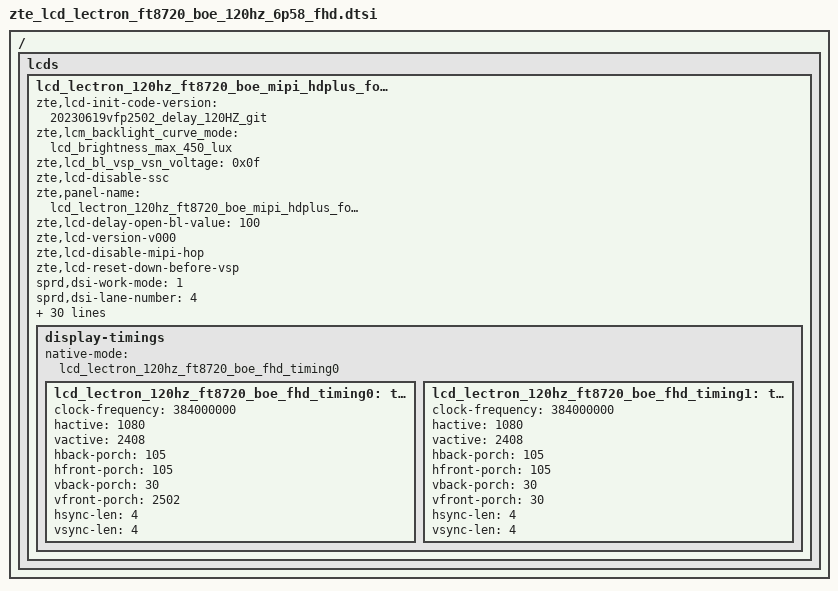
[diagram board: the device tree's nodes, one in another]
/ {
	fragment {
		target-path = "/";
		__overlay__ {
			lcds {
				lcd_lectron_120hz_ft8720_boe_mipi_hdplus_focal: lcd_lectron_120hz_ft8720_boe_mipi_hdplus_focal {
					zte,lcd-init-code-version = "20230619vfp2502_delay_120HZ_git";

					zte,lcm_backlight_curve_mode = "lcd_brightness_max_450_lux";
					zte,lcd_bl_vsp_vsn_voltage = <0x0f>;
					zte,lcd-disable-ssc;
					zte,panel-name = "lcd_lectron_120hz_ft8720_boe_mipi_hdplus_focal_vrr-3";
					zte,lcd-delay-open-bl-value = <100>;
					zte,lcd-version-v000;
					zte,lcd-disable-mipi-hop;
					zte,lcd-reset-down-before-vsp;

					sprd,dsi-work-mode = <1>;
					sprd,dsi-lane-number = <4>;
					sprd,dsi-color-format = "dsc";
					sprd,phy-bit-clock = <1100000>;
					sprd,phy-escape-clock = <20000>;/* kHz */

					sprd,width-mm = <68430>;
					sprd,height-mm = <152570>;
					sprd,vrr-enabled;
					sprd,vrr-max-layers = <3>;
					sprd,slice-width = <540>;
					sprd,slice-height = <8>;
					sprd,output-bpc = <8>;
					sprd,dsc-enable = <1>;
					sprd,dual-dsi-enable = <0>;
					zte,dsc-mode = <5>;

					sprd,esd-check-enable = <1>;/* 0:close , 1:open */
					sprd,esd-check-mode = <1>;/* 0:REG ,1:TE  */
					sprd,esd-check-period = <2000>;
					sprd,esd-check-register = <0x0A>;
					sprd,esd-check-value = <0x9C>;

					sprd,dphy-taget-val = <5>;

					sprd,reset-on-sequence = <1 5>, <0 10>, <1 35>;
					sprd,reset-off-sequence = <1 20>;

					sprd,use-gen-write;
					sprd,initial-command = [
29 00 00 02 00 00
29 00 00 04 FF 87 20 01
29 00 00 02 00 80
29 00 00 03 FF 87 20
29 00 00 02 00 00
29 00 00 05 2A 00 00 04 37
29 00 00 02 00 00
29 00 00 05 2B 00 00 09 67
29 00 00 02 00 A3
29 00 00 05 B3 09 68 00 18
29 00 00 02 00 80
29 00 00 07 C0 00 4B 00 2E 00 12
29 00 00 02 00 90
29 00 00 07 C0 00 4B 00 2E 00 12
29 00 00 02 00 A0
29 00 00 07 C0 00 62 03 F8 00 12
29 00 00 02 00 B0
29 00 00 06 C0 00 C1 00 2E 12
29 00 00 02 00 60
29 00 00 07 C0 00 A6 00 2E 00 12
29 00 00 02 00 70
29 00 00 0D C0 00 C4 00 C8 0F 02 CF 00 00 13 01 56
29 00 00 02 00 A3
29 00 00 07 C1 00 6E 00 34 00 02
29 00 00 02 00 80
29 00 00 11 CE 01 81 FF FF 00 FC 01 00 00 00 00 00 00 84 00 84
29 00 00 02 00 90
29 00 00 10 CE 00 AD 0F B9 00 AD 80 FF FF 00 06 40 0D 0C 00
29 00 00 02 00 A0
29 00 00 04 CE 00 00 00
29 00 00 02 00 B0
29 00 00 04 CE 22 00 00
29 00 00 02 00 D1
29 00 00 08 CE 00 00 01 00 00 00 00
29 00 00 02 00 E1
29 00 00 0C CE 07 02 CF 02 CF 00 00 00 00 00 00
29 00 00 02 00 F1
29 00 00 0A CE 27 1B 00 00 F5 01 0B 00 00
29 00 00 02 00 B0
29 00 00 05 CF 00 00 D6 DA
29 00 00 02 00 B5
29 00 00 05 CF 05 05 1D 21
29 00 00 02 00 C0
29 00 00 05 CF 09 09 63 67
29 00 00 02 00 C5
29 00 00 05 CF 09 09 69 6D
29 00 00 02 00 D1
29 00 00 0D C1 0A DF 0F 1A 19 CB 0A DF 0F 1A 19 CB
29 00 00 02 00 E1
29 00 00 03 C1 0F 1A
29 00 00 02 00 E4
29 00 00 0D CF 0D C4 0D C3 0D C3 0D C3 0D C3 0D C3
29 00 00 02 00 80
29 00 00 03 C1 44 44
29 00 00 02 00 90
29 00 00 02 C1 03
29 00 00 02 00 F5
29 00 00 02 CF 02
29 00 00 02 00 F6
29 00 00 02 CF 78
29 00 00 02 00 F1
29 00 00 02 CF 78
29 00 00 02 00 F0
29 00 00 02 C1 00
29 00 00 02 00 CC
29 00 00 02 C1 18
29 00 00 02 00 80
29 00 00 02 C5 88
29 00 00 02 00 91
29 00 00 02 C4 08
29 00 00 02 00 80
29 00 00 09 C2 83 01 03 86 82 01 03 86
29 00 00 02 00 A0
29 00 00 10 C2 8A 07 00 03 86 89 08 00 03 86 88 09 00 03 86
29 00 00 02 00 B0
29 00 00 06 C2 87 0A 00 03 86
29 00 00 02 00 E0
29 00 00 05 C2 33 33 00 00
29 00 00 02 00 E8
29 00 00 09 C2 12 00 0A 0A 03 88 00 00
29 00 00 02 00 D0
29 00 00 11 C3 35 0A 00 00 35 0A 00 00 35 0A 00 00 35 0A 00 00
29 00 00 02 00 E0
29 00 00 11 C3 35 0A 00 00 35 0A 00 00 35 0A 00 00 35 0A 00 00
29 00 00 02 00 80
29 00 00 11 CB CD CD CC 00 CD CC 00 CD CE FE CD 00 CC CC 00 00
29 00 00 02 00 90
29 00 00 11 CB 0C 00 00 00 0C 0C 00 00 0C 00 00 00 00 00 00 00
29 00 00 02 00 A0
29 00 00 09 CB 00 00 00 00 00 00 00 00
29 00 00 02 00 B0
29 00 00 05 CB 50 41 A4 00
29 00 00 02 00 C0
29 00 00 05 CB 50 41 A4 00
29 00 00 02 00 D5
29 00 00 0C CB 83 00 83 83 00 83 83 00 83 83 00
29 00 00 02 00 E0
29 00 00 0E CB 83 83 00 83 83 00 83 83 00 83 83 00 83
29 00 00 02 00 80
29 00 00 11 CC 26 23 20 20 1D 1D 18 17 16 18 17 16 1E 07 06 09
29 00 00 02 00 90
29 00 00 09 CC 08 01 1F 1F 20 1C 03 02
29 00 00 02 00 80
29 00 00 11 CD 26 23 20 20 1D 1D 18 17 16 18 17 16 1E 07 06 09
29 00 00 02 00 90
29 00 00 09 CD 08 01 1F 1F 20 1C 03 02
29 00 00 02 00 A0
29 00 00 11 CC 26 23 20 20 1D 1D 18 17 16 18 17 16 1E 08 09 06
29 00 00 02 00 B0
29 00 00 09 CC 07 01 1F 1F 1C 20 02 03
29 00 00 02 00 A0
29 00 00 11 CD 26 23 20 20 1D 1D 18 17 16 18 17 16 1E 08 09 06
29 00 00 02 00 B0
29 00 00 09 CD 07 01 1F 1F 1C 20 02 03
29 00 00 02 00 86
29 00 00 07 C0 00 00 00 01 12 04
29 00 00 02 00 96
29 00 00 07 C0 00 00 00 01 12 04
29 00 00 02 00 A6
29 00 00 07 C0 01 03 00 01 18 04
29 00 00 02 00 A3
29 00 00 07 CE 00 00 00 01 12 04
29 00 00 02 00 B3
29 00 00 07 CE 00 00 00 01 12 04
29 00 00 02 00 66
29 00 00 07 C0 01 05 00 01 1F 05
29 00 00 02 00 93
29 00 00 02 C5 23
29 00 00 02 00 97
29 00 00 02 C5 23
29 00 00 02 00 9A
29 00 00 02 C5 23
29 00 00 02 00 9C
29 00 00 02 C5 23
29 00 00 02 00 B6
29 00 00 09 C5 0F 0F 0F 0F 0F 0F 0F 0F
29 00 00 02 00 00
29 00 00 03 D8 2D 2D
29 00 00 02 00 88
29 00 00 02 C4 08
29 00 00 02 00 80
29 00 00 02 A7 03
29 00 00 02 00 B1
29 00 00 02 F5 1F
29 00 00 02 00 CB
29 00 00 02 C0 01
29 00 00 02 00 9B
29 00 00 02 C4 FF
29 00 00 02 00 94
29 00 00 02 E9 FF
29 00 00 02 00 9A
29 00 00 02 C4 11
29 00 00 02 00 95
29 00 00 02 E9 10
29 00 00 02 00 00
29 00 00 29 E1 00 04 09 11 24 1B 23 29 33 46 3B 42 47 4C 8F 51 59 60 67 54 6D 74 7B 84 EC 8D 92 98 A0 2C A8 B3 C0 C9 9E D5 E6 F4 FF 28
29 00 00 02 00 30
29 00 00 29 E1 00 04 09 11 24 1B 23 29 33 46 3B 42 47 4C 8F 51 59 60 67 54 6D 74 7B 84 EC 8D 92 98 A0 2C A8 B3 C0 C9 9E D5 E6 F4 FF 28
29 00 00 02 00 60
29 00 00 29 E1 00 04 09 11 24 1B 23 29 33 46 3B 42 47 4C 8F 51 59 60 67 54 6D 74 7B 84 EC 8D 92 98 A0 2C A8 B3 C0 C9 9E D5 E6 F4 FF 28
29 00 00 02 00 90
29 00 00 29 E1 00 04 09 11 24 1B 23 29 33 46 3B 42 47 4C 8F 51 59 60 67 54 6D 74 7B 84 EC 8D 92 98 A0 2C A8 B3 C0 C9 9E D5 E6 F4 FF 28
29 00 00 02 00 C0
29 00 00 29 E1 00 04 09 11 24 1B 23 29 33 46 3B 42 47 4C 8F 51 59 60 67 54 6D 74 7B 84 EC 8D 92 98 A0 2C A8 B3 C0 C9 9E D5 E6 F4 FF 28
29 00 00 02 00 F0
29 00 00 11 E1 00 04 09 11 24 1B 23 29 33 46 3B 42 47 4C 8F 51
29 00 00 02 00 00
29 00 00 19 E2 59 60 67 54 6D 74 7B 84 EC 8D 92 98 A0 2C A8 B3 C0 C9 9E D5 E6 F4 FF 28
29 00 00 02 00 8C
29 00 00 04 C3 03 00 30
29 00 00 02 00 80
29 00 00 02 B3 22
29 00 00 02 00 B0
29 00 00 02 B3 00
29 00 00 02 00 83
29 00 00 02 B0 63
29 00 00 02 00 82
29 00 00 02 F5 00
29 00 00 02 00 93
29 00 00 02 F5 00
29 00 00 02 00 9B
29 00 00 02 F5 49
29 00 00 02 00 9D
29 00 00 02 F5 49
29 00 00 02 00 BE
29 00 00 03 C5 F0 F0
29 00 00 02 00 8A
29 00 00 02 F5 C9
29 00 00 02 00 99
29 00 00 02 CF 50
29 00 00 02 00 9C
29 00 00 02 F5 00
29 00 00 02 00 9E
29 00 00 02 F5 00
29 00 00 02 00 B0
29 00 00 07 C5 C0 4A 3D C0 4A 0F
29 00 00 02 00 8A
29 00 00 02 C5 02
29 00 00 02 00 8D
29 00 00 02 C5 03
29 00 00 02 00 A0
29 00 00 02 A5 07
29 00 00 02 00 E8
29 00 00 02 C0 40
29 00 00 02 00 E0
29 00 00 02 CF 34
29 00 00 02 00 A0
29 00 00 02 C5 40
29 00 00 02 00 A1
29 00 00 02 C5 40
29 00 00 02 00 9D
29 00 00 02 C5 44
29 00 00 02 00 94
29 00 00 02 C5 04
29 00 00 02 00 98
29 00 00 02 C5 24
29 00 00 02 00 92
29 00 00 02 CF 12
29 00 00 02 00 84
29 00 00 02 A4 01
29 00 00 02 00 80
29 00 00 03 A6 00 12
29 00 00 02 00 90
29 00 00 02 A7 16
29 00 00 02 00 82
29 00 00 03 CE 11 11
29 00 00 02 00 B0
29 00 00 0F B4 00 08 02 00 00 BB 00 07 0D B7 0C B7 10 F0
29 00 00 02 00 80
29 00 00 02 CE 00
29 00 00 02 00 A1
29 00 00 02 C1 CC
29 00 00 02 00 AE
29 00 00 02 C1 FF
29 00 00 02 00 FC
29 00 00 02 C0 00
29 00 00 02 00 FD
29 00 00 02 C0 17
29 00 00 02 00 00
29 00 00 04 FF FF FF FF
29 00 00 02 35 00
05 78 00 01 11
05 14 00 01 29
					];

					zte,initial-command-fps120 = [
29 00 00 02 00 00
29 00 00 04 FF 87 20 01
29 00 00 02 00 80
29 00 00 03 FF 87 20
29 00 00 02 00 00
29 00 00 05 2A 00 00 04 37
29 00 00 02 00 00
29 00 00 05 2B 00 00 09 67
29 00 00 02 00 A3
29 00 00 05 B3 09 68 00 18
29 00 00 02 00 80
29 00 00 07 C0 00 4B 00 2E 00 12
29 00 00 02 00 90
29 00 00 07 C0 00 4B 00 2E 00 12
29 00 00 02 00 A0
29 00 00 07 C0 00 62 03 F8 00 12
29 00 00 02 00 B0
29 00 00 06 C0 00 C1 00 2E 12
29 00 00 02 00 60
29 00 00 07 C0 00 A6 00 2E 00 12
29 00 00 02 00 70
29 00 00 0D C0 00 C4 00 C8 0F 02 CF 00 00 13 01 56
29 00 00 02 00 A3
29 00 00 07 C1 00 6E 00 34 00 02
29 00 00 02 00 80
29 00 00 11 CE 01 81 FF FF 00 FC 01 00 00 00 00 00 00 84 00 84
29 00 00 02 00 90
29 00 00 10 CE 00 AD 0F B9 00 AD 80 FF FF 00 06 40 0D 0C 00
29 00 00 02 00 A0
29 00 00 04 CE 00 00 00
29 00 00 02 00 B0
29 00 00 04 CE 22 00 00
29 00 00 02 00 D1
29 00 00 08 CE 00 00 01 00 00 00 00
29 00 00 02 00 E1
29 00 00 0C CE 07 02 CF 02 CF 00 00 00 00 00 00
29 00 00 02 00 F1
29 00 00 0A CE 27 1B 00 00 F5 01 0B 00 00
29 00 00 02 00 B0
29 00 00 05 CF 00 00 D6 DA
29 00 00 02 00 B5
29 00 00 05 CF 05 05 1D 21
29 00 00 02 00 C0
29 00 00 05 CF 09 09 63 67
29 00 00 02 00 C5
29 00 00 05 CF 09 09 69 6D
29 00 00 02 00 D1
29 00 00 0D C1 0A DF 0F 1A 19 CB 0A DF 0F 1A 19 CB
29 00 00 02 00 E1
29 00 00 03 C1 0F 1A
29 00 00 02 00 E4
29 00 00 0D CF 0D C4 0D C3 0D C3 0D C3 0D C3 0D C3
29 00 00 02 00 80
29 00 00 03 C1 44 44
29 00 00 02 00 90
29 00 00 02 C1 03
29 00 00 02 00 F5
29 00 00 02 CF 02
29 00 00 02 00 F6
29 00 00 02 CF 78
29 00 00 02 00 F1
29 00 00 02 CF 78
29 00 00 02 00 F0
29 00 00 02 C1 00
29 00 00 02 00 CC
29 00 00 02 C1 18
29 00 00 02 00 80
29 00 00 02 C5 88
29 00 00 02 00 91
29 00 00 02 C4 08
29 00 00 02 00 80
29 00 00 09 C2 83 01 03 86 82 01 03 86
29 00 00 02 00 A0
29 00 00 10 C2 8A 07 00 03 86 89 08 00 03 86 88 09 00 03 86
29 00 00 02 00 B0
29 00 00 06 C2 87 0A 00 03 86
29 00 00 02 00 E0
29 00 00 05 C2 33 33 00 00
29 00 00 02 00 E8
29 00 00 09 C2 12 00 0A 0A 03 88 00 00
29 00 00 02 00 D0
29 00 00 11 C3 35 0A 00 00 35 0A 00 00 35 0A 00 00 35 0A 00 00
29 00 00 02 00 E0
29 00 00 11 C3 35 0A 00 00 35 0A 00 00 35 0A 00 00 35 0A 00 00
29 00 00 02 00 80
29 00 00 11 CB CD CD CC 00 CD CC 00 CD CE FE CD 00 CC CC 00 00
29 00 00 02 00 90
29 00 00 11 CB 0C 00 00 00 0C 0C 00 00 0C 00 00 00 00 00 00 00
29 00 00 02 00 A0
29 00 00 09 CB 00 00 00 00 00 00 00 00
29 00 00 02 00 B0
29 00 00 05 CB 50 41 A4 00
29 00 00 02 00 C0
29 00 00 05 CB 50 41 A4 00
29 00 00 02 00 D5
29 00 00 0C CB 83 00 83 83 00 83 83 00 83 83 00
29 00 00 02 00 E0
29 00 00 0E CB 83 83 00 83 83 00 83 83 00 83 83 00 83
29 00 00 02 00 80
29 00 00 11 CC 26 23 20 20 1D 1D 18 17 16 18 17 16 1E 07 06 09
29 00 00 02 00 90
29 00 00 09 CC 08 01 1F 1F 20 1C 03 02
29 00 00 02 00 80
29 00 00 11 CD 26 23 20 20 1D 1D 18 17 16 18 17 16 1E 07 06 09
29 00 00 02 00 90
29 00 00 09 CD 08 01 1F 1F 20 1C 03 02
29 00 00 02 00 A0
29 00 00 11 CC 26 23 20 20 1D 1D 18 17 16 18 17 16 1E 08 09 06
29 00 00 02 00 B0
29 00 00 09 CC 07 01 1F 1F 1C 20 02 03
29 00 00 02 00 A0
29 00 00 11 CD 26 23 20 20 1D 1D 18 17 16 18 17 16 1E 08 09 06
29 00 00 02 00 B0
29 00 00 09 CD 07 01 1F 1F 1C 20 02 03
29 00 00 02 00 86
29 00 00 07 C0 00 00 00 01 12 04
29 00 00 02 00 96
29 00 00 07 C0 00 00 00 01 12 04
29 00 00 02 00 A6
29 00 00 07 C0 01 03 00 01 18 04
29 00 00 02 00 A3
29 00 00 07 CE 00 00 00 01 12 04
29 00 00 02 00 B3
29 00 00 07 CE 00 00 00 01 12 04
29 00 00 02 00 66
29 00 00 07 C0 01 05 00 01 1F 05
29 00 00 02 00 93
29 00 00 02 C5 23
29 00 00 02 00 97
29 00 00 02 C5 23
29 00 00 02 00 9A
29 00 00 02 C5 23
29 00 00 02 00 9C
29 00 00 02 C5 23
29 00 00 02 00 B6
29 00 00 09 C5 0F 0F 0F 0F 0F 0F 0F 0F
29 00 00 02 00 00
29 00 00 03 D8 2D 2D
29 00 00 02 00 88
29 00 00 02 C4 08
29 00 00 02 00 80
29 00 00 02 A7 03
29 00 00 02 00 B1
29 00 00 02 F5 1F
29 00 00 02 00 CB
29 00 00 02 C0 01
29 00 00 02 00 9B
29 00 00 02 C4 FF
29 00 00 02 00 94
29 00 00 02 E9 FF
29 00 00 02 00 9A
29 00 00 02 C4 11
29 00 00 02 00 95
29 00 00 02 E9 10
29 00 00 02 00 00
29 00 00 29 E1 00 04 09 11 24 1B 23 29 33 46 3B 42 47 4C 8F 51 59 60 67 54 6D 74 7B 84 EC 8D 92 98 A0 2C A8 B3 C0 C9 9E D5 E6 F4 FF 28
29 00 00 02 00 30
29 00 00 29 E1 00 04 09 11 24 1B 23 29 33 46 3B 42 47 4C 8F 51 59 60 67 54 6D 74 7B 84 EC 8D 92 98 A0 2C A8 B3 C0 C9 9E D5 E6 F4 FF 28
29 00 00 02 00 60
29 00 00 29 E1 00 04 09 11 24 1B 23 29 33 46 3B 42 47 4C 8F 51 59 60 67 54 6D 74 7B 84 EC 8D 92 98 A0 2C A8 B3 C0 C9 9E D5 E6 F4 FF 28
29 00 00 02 00 90
29 00 00 29 E1 00 04 09 11 24 1B 23 29 33 46 3B 42 47 4C 8F 51 59 60 67 54 6D 74 7B 84 EC 8D 92 98 A0 2C A8 B3 C0 C9 9E D5 E6 F4 FF 28
29 00 00 02 00 C0
29 00 00 29 E1 00 04 09 11 24 1B 23 29 33 46 3B 42 47 4C 8F 51 59 60 67 54 6D 74 7B 84 EC 8D 92 98 A0 2C A8 B3 C0 C9 9E D5 E6 F4 FF 28
29 00 00 02 00 F0
29 00 00 11 E1 00 04 09 11 24 1B 23 29 33 46 3B 42 47 4C 8F 51
29 00 00 02 00 00
29 00 00 19 E2 59 60 67 54 6D 74 7B 84 EC 8D 92 98 A0 2C A8 B3 C0 C9 9E D5 E6 F4 FF 28
29 00 00 02 00 8C
29 00 00 04 C3 03 00 30
29 00 00 02 00 80
29 00 00 02 B3 22
29 00 00 02 00 B0
29 00 00 02 B3 00
29 00 00 02 00 83
29 00 00 02 B0 63
29 00 00 02 00 82
29 00 00 02 F5 00
29 00 00 02 00 93
29 00 00 02 F5 00
29 00 00 02 00 9B
29 00 00 02 F5 49
29 00 00 02 00 9D
29 00 00 02 F5 49
29 00 00 02 00 BE
29 00 00 03 C5 F0 F0
29 00 00 02 00 8A
29 00 00 02 F5 C9
29 00 00 02 00 99
29 00 00 02 CF 50
29 00 00 02 00 9C
29 00 00 02 F5 00
29 00 00 02 00 9E
29 00 00 02 F5 00
29 00 00 02 00 B0
29 00 00 07 C5 C0 4A 3D C0 4A 0F
29 00 00 02 00 8A
29 00 00 02 C5 02
29 00 00 02 00 8D
29 00 00 02 C5 03
29 00 00 02 00 A0
29 00 00 02 A5 07
29 00 00 02 00 E8
29 00 00 02 C0 40
29 00 00 02 00 E0
29 00 00 02 CF 34
29 00 00 02 00 A0
29 00 00 02 C5 40
29 00 00 02 00 A1
29 00 00 02 C5 40
29 00 00 02 00 9D
29 00 00 02 C5 44
29 00 00 02 00 94
29 00 00 02 C5 04
29 00 00 02 00 98
29 00 00 02 C5 24
29 00 00 02 00 92
29 00 00 02 CF 12
29 00 00 02 00 84
29 00 00 02 A4 01
29 00 00 02 00 80
29 00 00 03 A6 00 12
29 00 00 02 00 90
29 00 00 02 A7 16
29 00 00 02 00 82
29 00 00 03 CE 11 11
29 00 00 02 00 B0
29 00 00 0F B4 00 08 02 00 00 BB 00 07 0D B7 0C B7 10 F0
29 00 00 02 00 80
29 00 00 02 CE 00
29 00 00 02 00 A1
29 00 00 02 C1 CC
29 00 00 02 00 AE
29 00 00 02 C1 FF
29 00 00 02 00 FC
29 00 00 02 C0 00
29 00 00 02 00 FD
29 00 00 02 C0 17
29 00 00 02 00 00
29 00 00 04 FF FF FF FF
29 00 00 02 35 00
05 78 00 01 11
05 14 00 01 29
					];

					sprd,sleep-in-command = [
						15 0A 00 01 28
						15 C8 00 01 10
						29 00 00 02 00 00
						29 00 00 04 FF 87 20 01
						29 00 00 02 00 80
						29 00 00 03 FF 87 20
						29 00 00 02 00 00
						29 14 00 05 F7 5A A5 95 27
						];
					sprd,sleep-out-command = [
						05 78 00 01 11
						05 32 00 01 29
						];
/*zte,fps-to-fps120 = [
	29 00 00 02 00 00
	29 00 00 04 FF 87 20 01
	29 00 00 02 00 D2
	29 00 00 02 C0 00
	29 00 00 02 00 A7
	29 00 00 02 CE 12
	29 00 00 02 00 B7
	29 00 00 02 CE 12
	29 00 00 02 00 E4
	29 00 00 0D CF 09 FA 09 F9 09 F9 09 F9 09 F9 09 F9
	29 00 00 02 00 B0
	29 00 00 05 CF 00 00 D6 DA
	29 00 00 02 00 B5
	29 00 00 05 CF 05 05 1D 21
	29 00 00 02 00 F1
	29 00 00 02 CF 78
	29 00 00 02 00 F6
	29 00 00 02 CF 78
];
zte,fps90-to-fps60 = [
	29 00 00 02 00 00
	29 00 00 04 FF 87 20 01
	29 00 00 02 00 D2
	29 00 00 02 C0 01
	29 00 00 02 00 A7
	29 00 00 02 CE 18
	29 00 00 02 00 B7
	29 00 00 02 CE 18
	29 00 00 02 00 E4
	29 00 00 0D CF 0D C4 0D C3 0D C3 0D C3 0D C3 0D C3
	29 00 00 02 00 B0
	29 00 00 05 CF 00 00 66 6A
	29 00 00 02 00 B5
	29 00 00 05 CF 04 04 E5 E9
	29 00 00 02 00 F1
	29 00 00 02 CF 5A
	29 00 00 02 00 F6
	29 00 00 02 CF 3C
];*/
					display-timings {
						native-mode = <&lcd_lectron_120hz_ft8720_boe_fhd_timing0>;
						lcd_lectron_120hz_ft8720_boe_fhd_timing0: timing0 {
							clock-frequency = <384000000>;
							hactive = <1080>;
							vactive = <2408>; /*2408*/
							hback-porch = <105>;
							hfront-porch = <105>;
							vback-porch = <30>;
							vfront-porch = <2502>;
							hsync-len = <4>;
							vsync-len = <4>;
						};
						lcd_lectron_120hz_ft8720_boe_fhd_timing1: timing1 {
							clock-frequency = <384000000>;
							hactive = <1080>;
							vactive = <2408>; 
							hback-porch = <105>;
							hfront-porch = <105>;
							vback-porch = <30>;
							vfront-porch = <30>;
							hsync-len = <4>;
							vsync-len = <4>;
						};
					};
				};
			};
		};
	};
};
